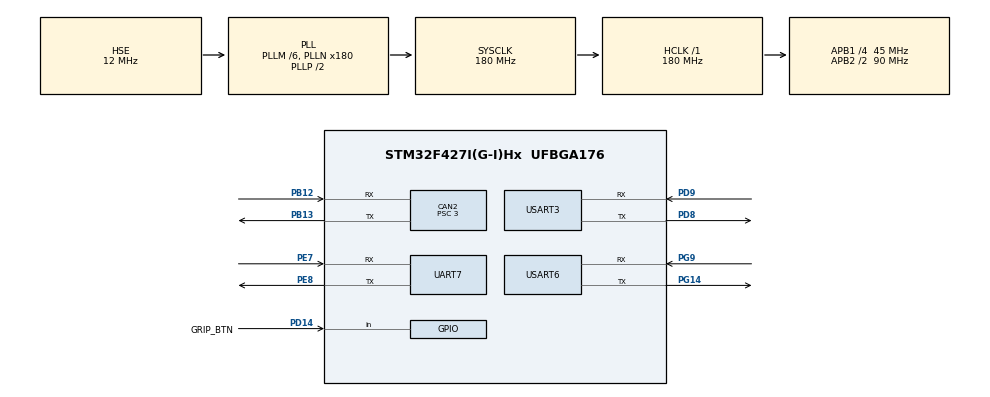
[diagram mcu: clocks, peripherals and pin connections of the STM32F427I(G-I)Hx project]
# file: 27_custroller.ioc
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CAN2.ABOM=ENABLE
CAN2.BS1=CAN_BS1_10TQ
CAN2.BS2=CAN_BS2_4TQ
CAN2.CalculateBaudRate=1000000
CAN2.CalculateTimeBit=1000
CAN2.CalculateTimeQuantum=66.66666666666666
CAN2.NART=ENABLE
CAN2.Prescaler=3
FREERTOS.Tasks01=defaultTask,0,128,StartDefaultTask,Default,NULL,Dynamic,NULL,NULL;ControlTask,2,512,StartControlTask,Default,NULL,Dynamic,NULL,NULL;CommTask,0,512,StartCommTask,Default,NULL,Dynamic,NULL,NULL
Mcu.Family=STM32F4
Mcu.Name=STM32F427I(G-I)Hx
Mcu.Package=UFBGA176
NVIC.CAN2_RX0_IRQn=true\:5\:0\:false\:false\:true\:true\:true\:true\:true
NVIC.PriorityGroup=NVIC_PRIORITYGROUP_4
NVIC.TIM7_IRQn=true\:15\:0\:false\:false\:true\:false\:false\:true\:true
NVIC.TimeBase=TIM7_IRQn
NVIC.TimeBaseIP=TIM7
NVIC.UART7_IRQn=true\:5\:0\:false\:false\:true\:true\:true\:true\:true
NVIC.USART3_IRQn=true\:5\:0\:false\:false\:true\:true\:true\:true\:true
NVIC.USART6_IRQn=true\:5\:0\:false\:false\:true\:true\:true\:true\:true
PA13.Mode=Serial_Wire
PA13.Signal=SYS_JTMS-SWDIO
PA14.Mode=Serial_Wire
PA14.Signal=SYS_JTCK-SWCLK
PB12.Mode=CAN_Activate
PB12.Signal=CAN2_RX
PB13.Mode=CAN_Activate
PB13.Signal=CAN2_TX
PD14.GPIO_Label=GRIP_BTN
PD14.GPIO_PuPd=GPIO_PULLDOWN
PD14.Signal=GPIO_Input
PD8.Mode=Asynchronous
PD8.Signal=USART3_TX
PD9.Mode=Asynchronous
PD9.Signal=USART3_RX
PE7.Mode=Asynchronous
PE7.Signal=UART7_RX
PE8.Mode=Asynchronous
PE8.Signal=UART7_TX
PG14.Mode=Asynchronous
PG14.Signal=USART6_TX
PG9.Mode=Asynchronous
PG9.Signal=USART6_RX
PH0/OSC_IN.Mode=HSE-External-Oscillator
PH0/OSC_IN.Signal=RCC_OSC_IN
PH1/OSC_OUT.Mode=HSE-External-Oscillator
PH1/OSC_OUT.Signal=RCC_OSC_OUT
ProjectManager.HeapSize=0x400
ProjectManager.StackSize=0x800
ProjectManager.TargetToolchain=MDK-ARM V5.32
RCC.48MHZClocksFreq_Value=90000000
RCC.AHBFreq_Value=180000000
RCC.APB1CLKDivider=RCC_HCLK_DIV4
RCC.APB1Freq_Value=45000000
RCC.APB1TimFreq_Value=90000000
RCC.APB2CLKDivider=RCC_HCLK_DIV2
RCC.APB2Freq_Value=90000000
RCC.APB2TimFreq_Value=180000000
RCC.CortexFreq_Value=180000000
RCC.HCLKFreq_Value=180000000
RCC.HSE_VALUE=12000000
RCC.HSI_VALUE=16000000
RCC.LSE_VALUE=32768
RCC.PLLM=6
RCC.PLLN=180
RCC.PLLSourceVirtual=RCC_PLLSOURCE_HSE
RCC.SYSCLKFreq_VALUE=180000000
RCC.SYSCLKSource=RCC_SYSCLKSOURCE_PLLCLK
RCC.VCOOutputFreq_Value=360000000
UART7.VirtualMode=Asynchronous
USART3.VirtualMode=VM_ASYNC
USART6.VirtualMode=VM_ASYNC
VP_FREERTOS_VS_CMSIS_V1.Mode=CMSIS_V1
VP_SYS_VS_tim7.Mode=TIM7
board=custom

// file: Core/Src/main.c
/* USER CODE BEGIN Header */
/**
  ******************************************************************************
  * @file           : main.c
  * @brief          : Main program body
  ******************************************************************************
  * @attention
  *
  * Copyright (c) 2026 STMicroelectronics.
  * All rights reserved.
  *
  * This software is licensed under terms that can be found in the LICENSE file
  * in the root directory of this software component.
  * If no LICENSE file comes with this software, it is provided AS-IS.
  *
  ******************************************************************************
  */
/* USER CODE END Header */
#include "main.h"
#include "cmsis_os.h"
#include "can.h"
#include "usart.h"
#include "gpio.h"

/* USER CODE BEGIN Includes */
#include "zigbee.h"
/* USER CODE END Includes */

void SystemClock_Config(void);
void MX_FREERTOS_Init(void);

int main(void)
{

  /* MCU Configuration--------------------------------------------------------*/

  /* Reset of all peripherals, Initializes the Flash interface and the Systick. */
 HAL_Init();

  /* Configure the system clock */
  SystemClock_Config();

  /* Initialize all configured peripherals */
  MX_GPIO_Init();
  MX_CAN2_Init();
  MX_USART6_UART_Init();
  MX_UART7_Init();
  MX_USART3_UART_Init();

  /* Call init function for freertos objects (in cmsis_os2.c) */
  MX_FREERTOS_Init();

  /* Start scheduler */
  osKernelStart();

  /* We should never get here as control is now taken by the scheduler */

  /* Infinite loop */
  while (1)
  {

  }
}

void SystemClock_Config(void)
{
  RCC_OscInitTypeDef RCC_OscInitStruct = {0};
  RCC_ClkInitTypeDef RCC_ClkInitStruct = {0};

  /** Configure the main internal regulator output voltage
  */
  __HAL_RCC_PWR_CLK_ENABLE();
  __HAL_PWR_VOLTAGESCALING_CONFIG(PWR_REGULATOR_VOLTAGE_SCALE1);

  /** Initializes the RCC Oscillators according to the specified parameters
  * in the RCC_OscInitTypeDef structure.
  */
  RCC_OscInitStruct.OscillatorType = RCC_OSCILLATORTYPE_HSE;
  RCC_OscInitStruct.HSEState = RCC_HSE_ON;
  RCC_OscInitStruct.PLL.PLLState = RCC_PLL_ON;
  RCC_OscInitStruct.PLL.PLLSource = RCC_PLLSOURCE_HSE;
  RCC_OscInitStruct.PLL.PLLM = 6;
  RCC_OscInitStruct.PLL.PLLN = 180;
  RCC_OscInitStruct.PLL.PLLP = RCC_PLLP_DIV2;
  RCC_OscInitStruct.PLL.PLLQ = 4;
  if (HAL_RCC_OscConfig(&RCC_OscInitStruct) != HAL_OK)
  {
    Error_Handler();
  }

  /** Activate the Over-Drive mode
  */
  if (HAL_PWREx_EnableOverDrive() != HAL_OK)
  {
    Error_Handler();
  }

  /** Initializes the CPU, AHB and APB buses clocks
  */
  RCC_ClkInitStruct.ClockType = RCC_CLOCKTYPE_HCLK|RCC_CLOCKTYPE_SYSCLK
                              |RCC_CLOCKTYPE_PCLK1|RCC_CLOCKTYPE_PCLK2;
  RCC_ClkInitStruct.SYSCLKSource = RCC_SYSCLKSOURCE_PLLCLK;
  RCC_ClkInitStruct.AHBCLKDivider = RCC_SYSCLK_DIV1;
  RCC_ClkInitStruct.APB1CLKDivider = RCC_HCLK_DIV4;
  RCC_ClkInitStruct.APB2CLKDivider = RCC_HCLK_DIV2;

  if (HAL_RCC_ClockConfig(&RCC_ClkInitStruct, FLASH_LATENCY_5) != HAL_OK)
  {
    Error_Handler();
  }
}

void HAL_TIM_PeriodElapsedCallback(TIM_HandleTypeDef *htim)
{
  if (htim->Instance == TIM7)
  {
    HAL_IncTick();
  }
}

void Error_Handler(void)
{
  __disable_irq();
  while (1)
  {
  }
}

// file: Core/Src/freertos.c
/* USER CODE BEGIN Header */
/**
  ******************************************************************************
  * File Name          : freertos.c
  * Description        : Code for freertos applications
  ******************************************************************************
  * @attention
  *
  * Copyright (c) 2026 STMicroelectronics.
  * All rights reserved.
  *
  * This software is licensed under terms that can be found in the LICENSE file
  * in the root directory of this software component.
  * If no LICENSE file comes with this software, it is provided AS-IS.
  *
  ******************************************************************************
  */
/* USER CODE END Header */

#include "FreeRTOS.h"
#include "task.h"
#include "main.h"
#include "cmsis_os.h"

/* USER CODE BEGIN Includes */
#include "task_arm_control.h"
#include "task_telemetry.h"

/* ★ 防 CubeMX 覆盖（2026-10-29 加）
 *
 * configCHECK_FOR_STACK_OVERFLOW 在 .ioc 里没有对应条目，所以每次在 CubeMX 里
 * "GENERATE CODE"，它都会被从 FreeRTOSConfig.h 里删掉。删掉之后栈溢出不再被
 * 捕获，CommTask 里 snprintf(%.3f x12) 需要的近 900 字节一旦超出 1KB 栈，
 * 就会静默踩坏相邻的 ControlTask —— 现象是"电机全部失能、机械臂完全不动"，
 * 而且没有任何报错，极难定位。
 *
 * 这里让它在编译期就失败，比等上板才发现强得多。
 * Compile-time guard so a CubeMX regeneration can never silently ship a
 * build with stack-overflow checking disabled.
 *
 * 顺带：CommTask 的栈已经写进 .ioc（512 words），CubeMX 会正确生成。
 * 这一条 .ioc 带不出来，只能靠这个断言守。 */
#if (configCHECK_FOR_STACK_OVERFLOW < 2)
#error "CubeMX 删掉了 configCHECK_FOR_STACK_OVERFLOW！请到 Core/Inc/FreeRTOSConfig.h 恢复: #define configCHECK_FOR_STACK_OVERFLOW 2"
#endif

/* USER CODE END Includes */

osThreadId defaultTaskHandle;
osThreadId ControlTaskHandle;
osThreadId CommTaskHandle;

void StartDefaultTask(void const * argument);
void StartControlTask(void const * argument);
void StartCommTask(void const * argument);

void MX_FREERTOS_Init(void); /* (MISRA C 2004 rule 8.1) */

/* GetIdleTaskMemory prototype (linked to static allocation support) */
void vApplicationGetIdleTaskMemory( StaticTask_t **ppxIdleTaskTCBBuffer, StackType_t **ppxIdleTaskStackBuffer, uint32_t *pulIdleTaskStackSize );

/* USER CODE BEGIN GET_IDLE_TASK_MEMORY */
static StaticTask_t xIdleTaskTCBBuffer;
static StackType_t xIdleStack[configMINIMAL_STACK_SIZE];

void vApplicationGetIdleTaskMemory( StaticTask_t **ppxIdleTaskTCBBuffer, StackType_t **ppxIdleTaskStackBuffer, uint32_t *pulIdleTaskStackSize )
{
  *ppxIdleTaskTCBBuffer = &xIdleTaskTCBBuffer;
  *ppxIdleTaskStackBuffer = &xIdleStack[0];
  *pulIdleTaskStackSize = configMINIMAL_STACK_SIZE;
  /* place for user code */
}
/* USER CODE END GET_IDLE_TASK_MEMORY */

void MX_FREERTOS_Init(void) {

  /* Create the thread(s) */
  /* definition and creation of defaultTask */
  osThreadDef(defaultTask, StartDefaultTask, osPriorityNormal, 0, 128);
  defaultTaskHandle = osThreadCreate(osThread(defaultTask), NULL);

  /* definition and creation of ControlTask */
  osThreadDef(ControlTask, StartControlTask, osPriorityHigh, 0, 512);
  ControlTaskHandle = osThreadCreate(osThread(ControlTask), NULL);

  /* definition and creation of CommTask */
  osThreadDef(CommTask, StartCommTask, osPriorityNormal, 0, 512);
  CommTaskHandle = osThreadCreate(osThread(CommTask), NULL);

}

void StartDefaultTask(void const * argument)
{
  for(;;)
  {
    osDelay(1);
  }
}

void StartControlTask(void const * argument)
{
  /* USER CODE BEGIN StartControlTask */
  /* 挂载并进入机械臂核心控制任务（高优先级，~300Hz） */
  Task_ArmControl(argument);
  /* USER CODE END StartControlTask */
}

void StartCommTask(void const * argument)
{
  /* USER CODE BEGIN StartCommTask */
  /* 挂载并进入遥测任务（20Hz） */
  Task_Telemetry(argument);
  /* USER CODE END StartCommTask */
}

/* USER CODE BEGIN Application */
/**
  * @brief  栈溢出钩子（configCHECK_FOR_STACK_OVERFLOW == 2）。
  *         走到这里说明某个任务的栈已经踩穿了。这里直接停住等调试器接管，
  *         比让溢出静默改坏 heap_4 里相邻任务的栈 / TCB 安全得多。
  *         调试时在 Watch 里看 prvOverflowTaskName 就知道是哪个任务。
  */
volatile const char *prvOverflowTaskName = NULL;

void vApplicationStackOverflowHook(TaskHandle_t xTask, char *pcTaskName)
{
  (void)xTask;
  prvOverflowTaskName = pcTaskName;
  taskDISABLE_INTERRUPTS();
  for (;;)
  {
  }
}
/* USER CODE END Application */
